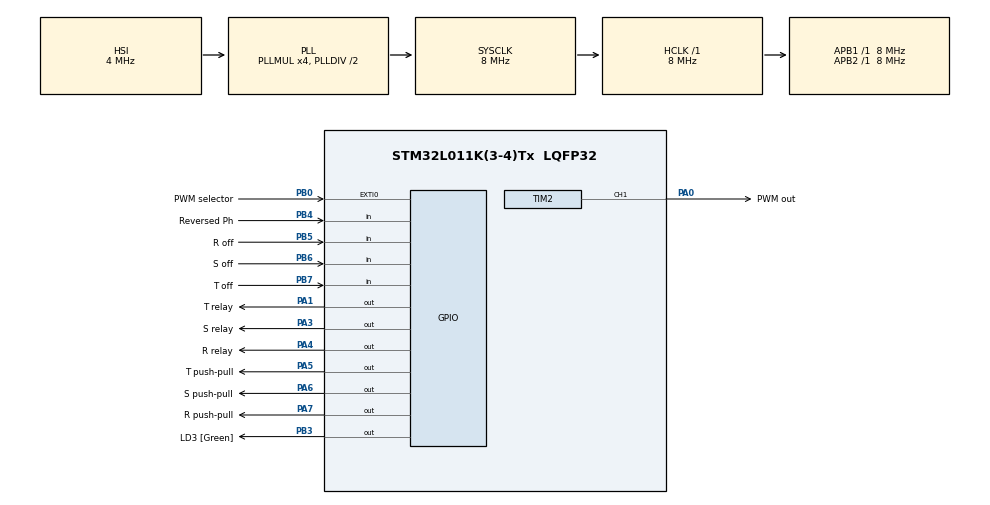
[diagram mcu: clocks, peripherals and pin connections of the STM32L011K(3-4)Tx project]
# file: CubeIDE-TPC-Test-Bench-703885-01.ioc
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Mcu.Family=STM32L0
PA0-CK_IN.GPIO_Label=PWM out
VP_IWDG_VS_IWDG.Mode=IWDG_Activate
PA14.GPIO_Label=TCK
PA6.GPIO_Label=S push-pull
PB0.GPIO_Label=PWM selector
PB6.GPIO_Label=S off
RCC.SYSCLKSource=RCC_SYSCLKSOURCE_PLLCLK
ProjectManager.StackSize=0x200
PA15.GPIO_Label=VCP_RX
TIM21.Period=26667
RCC.HCLKFreq_Value=8000000
RCC.APB2TimFreq_Value=8000000
PB6.Signal=GPIO_Input
RCC.AHBFreq_Value=8000000
RCC.HSE_VALUE=8000000
RCC.PLLMUL=RCC_PLLMUL_4
PB0.GPIO_ModeDefaultEXTI=GPIO_MODE_IT_RISING_FALLING
PA0-CK_IN.Signal=S_TIM2_CH1
PC14-OSC32_IN.Mode=LSE-External-Oscillator
PA14.Mode=Serial_Wire
PB7.Signal=GPIO_Input
TIM2.Channel-PWM\ Generation1\ CH1=TIM_CHANNEL_1
PB7.GPIO_Label=T off
Mcu.Package=LQFP32
PA6.Signal=GPIO_Output
PA2.GPIO_Label=VCP_TX
IWDG.Reload=867
PA15.Signal=USART2_RX
PB5.GPIO_Label=R off
RCC.APB1TimFreq_Value=8000000
PA4.GPIO_Label=R relay
TIM2.OC1Preload_PWM=DISABLE
RCC.HSI48_VALUE=48000000
PB4.Signal=GPIO_Input
PA3.Signal=GPIO_Output
PB3.GPIO_Label=LD3 [Green]
RCC.MSI_VALUE=2097000
PB7.GPIO_PuPd=GPIO_PULLUP
PC15-OSC32_OUT.Mode=LSE-External-Oscillator
SH.S_TIM2_CH1.0=TIM2_CH1,PWM Generation1 CH1
PB6.GPIO_PuPd=GPIO_PULLUP
PC14-OSC32_IN.Signal=RCC_OSC32_IN
TIM2.Pulse-PWM\ Generation1\ CH1=400
PA13.Signal=SYS_SWDIO
RCC.HSI16_VALUE=16000000
ProjectManager.TargetToolchain=STM32CubeIDE
PB4.GPIO_PuPd=GPIO_PULLUP
PC15-OSC32_OUT.Signal=RCC_OSC32_OUT
PA1.Signal=GPIO_Output
PA5.Signal=GPIO_Output
board=NUCLEO-L011K4
RCC.VCOOutputFreq_Value=16000000
RCC.HSIRCDiv=4
RCC.APB2Freq_Value=8000000
VP_TIM21_VS_ClockSourceINT.Mode=Internal
PB4.GPIO_Label=Reversed Ph
VP_TIM2_VS_ClockSourceINT.Mode=Internal
RCC.ADCFreq_Value=4000000
PA1.GPIO_Label=T relay
NVIC.TIM21_IRQn=true\:0\:0\:false\:false\:true\:true\:true
TIM2.Period=1600
PA13.Mode=Serial_Wire
Mcu.Name=STM32L011K(3-4)Tx
PA13.GPIO_Label=TMS
PA2.Signal=USART2_TX
PB3.Signal=GPIO_Output
PA4.Signal=GPIO_Output
RCC.SYSCLKFreq_VALUE=8000000
PB5.Signal=GPIO_Input
PA7.GPIO_Label=R push-pull
PA5.GPIO_Label=T push-pull
PB5.GPIO_PuPd=GPIO_PULLUP
PA14.Signal=SYS_SWCLK
ProjectManager.HeapSize=0x020
RCC.HSI_VALUE=4000000
IWDG.Prescaler=IWDG_PRESCALER_64
RCC.APB1Freq_Value=8000000
PB0.Signal=GPXTI0
IWDG.Window=4095
PB0.GPIO_PuPd=GPIO_PULLUP
PA3.GPIO_Label=S relay
PA7.Signal=GPIO_Output
NVIC.EXTI0_1_IRQn=true\:0\:0\:false\:false\:true\:true\:true

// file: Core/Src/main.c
/* USER CODE BEGIN Header */
/**
 ******************************************************************************
 * @file           : main.c
 * @brief          : Main program body
 ******************************************************************************
 * @attention
 *
 * <h2><center>&copy; Copyright (c) 2021 STMicroelectronics.
 * All rights reserved.</center></h2>
 *
 * This software component is licensed by ST under BSD 3-Clause license,
 * the "License"; You may not use this file except in compliance with the
 * License. You may obtain a copy of the License at:
 *                        opensource.org/licenses/BSD-3-Clause
 *
 ******************************************************************************
 */
/* USER CODE END Header */
#include "main.h"

IWDG_HandleTypeDef hiwdg;

TIM_HandleTypeDef htim2;
TIM_HandleTypeDef htim21;

void SystemClock_Config(void);
static void MX_GPIO_Init(void);
static void MX_TIM2_Init(void);
static void MX_TIM21_Init(void);
static void MX_IWDG_Init(void);

int main(void)
{

  /* MCU Configuration--------------------------------------------------------*/

  /* Reset of all peripherals, Initializes the Flash interface and the Systick. */
  HAL_Init();

  /* Configure the system clock */
  SystemClock_Config();

  /* Initialize all configured peripherals */
  MX_GPIO_Init();
  MX_TIM2_Init();
  MX_TIM21_Init();
  MX_IWDG_Init();
  /* USER CODE BEGIN 2 */
  HAL_TIM_OC_Start(&htim2, TIM_CHANNEL_1);
  HAL_TIM_Base_Start_IT(&htim21);
  /* USER CODE END 2 */

  /* Infinite loop */
  /* USER CODE BEGIN WHILE */
  uint8_t initialCount = 0;
  uint32_t firstDelayInMs = 850; // first flashes 85/15
  while (1) {
    REFRESH_PWM_DC
    HAL_IWDG_Refresh(&hiwdg);
    HAL_GPIO_WritePin(LD3_GPIO_Port, LD3_Pin, GPIO_PIN_SET);
    HAL_Delay(firstDelayInMs);
    HAL_GPIO_WritePin(LD3_GPIO_Port, LD3_Pin, GPIO_PIN_RESET);
    HAL_Delay(1000-firstDelayInMs);
    if(initialCount<10) {
      initialCount++;
    } else {
      firstDelayInMs = 100; // after around 10 seconds, flashes 10/90
    }

    /* USER CODE END WHILE */

  }
}

void SystemClock_Config(void)
{
  RCC_OscInitTypeDef RCC_OscInitStruct = {0};
  RCC_ClkInitTypeDef RCC_ClkInitStruct = {0};

  /** Configure the main internal regulator output voltage
  */
  __HAL_PWR_VOLTAGESCALING_CONFIG(PWR_REGULATOR_VOLTAGE_SCALE1);
  /** Initializes the RCC Oscillators according to the specified parameters
  * in the RCC_OscInitTypeDef structure.
  */
  RCC_OscInitStruct.OscillatorType = RCC_OSCILLATORTYPE_HSI|RCC_OSCILLATORTYPE_LSI;
  RCC_OscInitStruct.HSIState = RCC_HSI_DIV4;
  RCC_OscInitStruct.HSICalibrationValue = RCC_HSICALIBRATION_DEFAULT;
  RCC_OscInitStruct.LSIState = RCC_LSI_ON;
  RCC_OscInitStruct.PLL.PLLState = RCC_PLL_ON;
  RCC_OscInitStruct.PLL.PLLSource = RCC_PLLSOURCE_HSI;
  RCC_OscInitStruct.PLL.PLLMUL = RCC_PLLMUL_4;
  RCC_OscInitStruct.PLL.PLLDIV = RCC_PLLDIV_2;
  if (HAL_RCC_OscConfig(&RCC_OscInitStruct) != HAL_OK)
  {
    Error_Handler();
  }
  /** Initializes the CPU, AHB and APB buses clocks
  */
  RCC_ClkInitStruct.ClockType = RCC_CLOCKTYPE_HCLK|RCC_CLOCKTYPE_SYSCLK
                              |RCC_CLOCKTYPE_PCLK1|RCC_CLOCKTYPE_PCLK2;
  RCC_ClkInitStruct.SYSCLKSource = RCC_SYSCLKSOURCE_PLLCLK;
  RCC_ClkInitStruct.AHBCLKDivider = RCC_SYSCLK_DIV1;
  RCC_ClkInitStruct.APB1CLKDivider = RCC_HCLK_DIV1;
  RCC_ClkInitStruct.APB2CLKDivider = RCC_HCLK_DIV1;

  if (HAL_RCC_ClockConfig(&RCC_ClkInitStruct, FLASH_LATENCY_0) != HAL_OK)
  {
    Error_Handler();
  }
}

static void MX_IWDG_Init(void)
{

  hiwdg.Instance = IWDG;
  hiwdg.Init.Prescaler = IWDG_PRESCALER_64;
  hiwdg.Init.Window = 4095;
  hiwdg.Init.Reload = 867;
  if (HAL_IWDG_Init(&hiwdg) != HAL_OK)
  {
    Error_Handler();
  }

}

static void MX_TIM2_Init(void)
{

  TIM_ClockConfigTypeDef sClockSourceConfig = {0};
  TIM_MasterConfigTypeDef sMasterConfig = {0};
  TIM_OC_InitTypeDef sConfigOC = {0};

  htim2.Instance = TIM2;
  htim2.Init.Prescaler = 0;
  htim2.Init.CounterMode = TIM_COUNTERMODE_UP;
  htim2.Init.Period = 1600;
  htim2.Init.ClockDivision = TIM_CLOCKDIVISION_DIV1;
  htim2.Init.AutoReloadPreload = TIM_AUTORELOAD_PRELOAD_DISABLE;
  if (HAL_TIM_Base_Init(&htim2) != HAL_OK)
  {
    Error_Handler();
  }
  sClockSourceConfig.ClockSource = TIM_CLOCKSOURCE_INTERNAL;
  if (HAL_TIM_ConfigClockSource(&htim2, &sClockSourceConfig) != HAL_OK)
  {
    Error_Handler();
  }
  if (HAL_TIM_PWM_Init(&htim2) != HAL_OK)
  {
    Error_Handler();
  }
  sMasterConfig.MasterOutputTrigger = TIM_TRGO_RESET;
  sMasterConfig.MasterSlaveMode = TIM_MASTERSLAVEMODE_DISABLE;
  if (HAL_TIMEx_MasterConfigSynchronization(&htim2, &sMasterConfig) != HAL_OK)
  {
    Error_Handler();
  }
  sConfigOC.OCMode = TIM_OCMODE_PWM1;
  sConfigOC.Pulse = 400;
  sConfigOC.OCPolarity = TIM_OCPOLARITY_HIGH;
  sConfigOC.OCFastMode = TIM_OCFAST_DISABLE;
  if (HAL_TIM_PWM_ConfigChannel(&htim2, &sConfigOC, TIM_CHANNEL_1) != HAL_OK)
  {
    Error_Handler();
  }
  __HAL_TIM_DISABLE_OCxPRELOAD(&htim2, TIM_CHANNEL_1);
  HAL_TIM_MspPostInit(&htim2);

}

static void MX_TIM21_Init(void)
{

  TIM_ClockConfigTypeDef sClockSourceConfig = {0};
  TIM_MasterConfigTypeDef sMasterConfig = {0};

  htim21.Instance = TIM21;
  htim21.Init.Prescaler = 0;
  htim21.Init.CounterMode = TIM_COUNTERMODE_UP;
  htim21.Init.Period = 26667;
  htim21.Init.ClockDivision = TIM_CLOCKDIVISION_DIV1;
  htim21.Init.AutoReloadPreload = TIM_AUTORELOAD_PRELOAD_DISABLE;
  if (HAL_TIM_Base_Init(&htim21) != HAL_OK)
  {
    Error_Handler();
  }
  sClockSourceConfig.ClockSource = TIM_CLOCKSOURCE_INTERNAL;
  if (HAL_TIM_ConfigClockSource(&htim21, &sClockSourceConfig) != HAL_OK)
  {
    Error_Handler();
  }
  sMasterConfig.MasterOutputTrigger = TIM_TRGO_RESET;
  sMasterConfig.MasterSlaveMode = TIM_MASTERSLAVEMODE_DISABLE;
  if (HAL_TIMEx_MasterConfigSynchronization(&htim21, &sMasterConfig) != HAL_OK)
  {
    Error_Handler();
  }

}

static void MX_GPIO_Init(void)
{
  GPIO_InitTypeDef GPIO_InitStruct = {0};

  /* GPIO Ports Clock Enable */
  __HAL_RCC_GPIOC_CLK_ENABLE();
  __HAL_RCC_GPIOA_CLK_ENABLE();
  __HAL_RCC_GPIOB_CLK_ENABLE();

  /*Configure GPIO pin Output Level */
  HAL_GPIO_WritePin(GPIOA, T_relay_Pin|S_relay_Pin|R_relay_Pin|T_push_pull_Pin
                          |S_push_pull_Pin|R_push_pull_Pin, GPIO_PIN_RESET);

  /*Configure GPIO pin Output Level */
  HAL_GPIO_WritePin(LD3_GPIO_Port, LD3_Pin, GPIO_PIN_RESET);

  /*Configure GPIO pins : T_relay_Pin S_relay_Pin R_relay_Pin T_push_pull_Pin
                           S_push_pull_Pin R_push_pull_Pin */
  GPIO_InitStruct.Pin = T_relay_Pin|S_relay_Pin|R_relay_Pin|T_push_pull_Pin
                          |S_push_pull_Pin|R_push_pull_Pin;
  GPIO_InitStruct.Mode = GPIO_MODE_OUTPUT_PP;
  GPIO_InitStruct.Pull = GPIO_NOPULL;
  GPIO_InitStruct.Speed = GPIO_SPEED_FREQ_LOW;
  HAL_GPIO_Init(GPIOA, &GPIO_InitStruct);

  /*Configure GPIO pins : VCP_TX_Pin VCP_RX_Pin */
  GPIO_InitStruct.Pin = VCP_TX_Pin|VCP_RX_Pin;
  GPIO_InitStruct.Mode = GPIO_MODE_AF_PP;
  GPIO_InitStruct.Pull = GPIO_NOPULL;
  GPIO_InitStruct.Speed = GPIO_SPEED_FREQ_VERY_HIGH;
  GPIO_InitStruct.Alternate = GPIO_AF4_USART2;
  HAL_GPIO_Init(GPIOA, &GPIO_InitStruct);

  /*Configure GPIO pin : PWM_selector_Pin */
  GPIO_InitStruct.Pin = PWM_selector_Pin;
  GPIO_InitStruct.Mode = GPIO_MODE_IT_RISING_FALLING;
  GPIO_InitStruct.Pull = GPIO_PULLUP;
  HAL_GPIO_Init(PWM_selector_GPIO_Port, &GPIO_InitStruct);

  /*Configure GPIO pin : LD3_Pin */
  GPIO_InitStruct.Pin = LD3_Pin;
  GPIO_InitStruct.Mode = GPIO_MODE_OUTPUT_PP;
  GPIO_InitStruct.Pull = GPIO_NOPULL;
  GPIO_InitStruct.Speed = GPIO_SPEED_FREQ_LOW;
  HAL_GPIO_Init(LD3_GPIO_Port, &GPIO_InitStruct);

  /*Configure GPIO pins : Reversed_Ph_Pin R_off_Pin S_off_Pin T_off_Pin */
  GPIO_InitStruct.Pin = Reversed_Ph_Pin|R_off_Pin|S_off_Pin|T_off_Pin;
  GPIO_InitStruct.Mode = GPIO_MODE_INPUT;
  GPIO_InitStruct.Pull = GPIO_PULLUP;
  HAL_GPIO_Init(GPIOB, &GPIO_InitStruct);

  /* EXTI interrupt init*/
  HAL_NVIC_SetPriority(EXTI0_1_IRQn, 0, 0);
  HAL_NVIC_EnableIRQ(EXTI0_1_IRQn);

}

void Error_Handler(void)
{
  __disable_irq();
  while (1) {
  }
}

/************************ (C) COPYRIGHT STMicroelectronics *****END OF FILE****/
